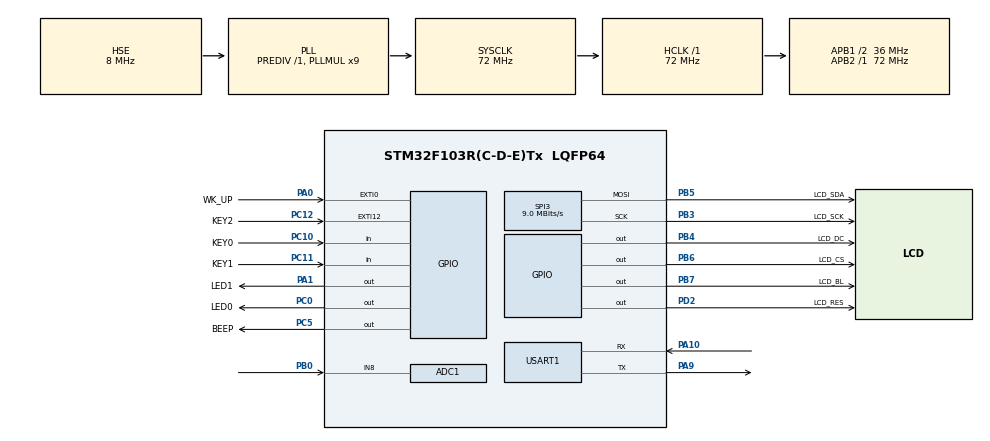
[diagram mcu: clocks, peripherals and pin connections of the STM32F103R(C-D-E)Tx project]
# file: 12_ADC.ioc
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ADC1.Channel-0\#ChannelRegularConversion=ADC_CHANNEL_8
ADC1.ContinuousConvMode=ENABLE
ADC1.NbrOfConversionFlag=1
ADC1.Rank-0\#ChannelRegularConversion=1
ADC1.SamplingTime-0\#ChannelRegularConversion=ADC_SAMPLETIME_1CYCLE_5
ADC1.master=1
Mcu.Family=STM32F1
Mcu.Name=STM32F103R(C-D-E)Tx
Mcu.Package=LQFP64
NVIC.EXTI0_IRQn=true\:2\:0\:true\:false\:true\:true\:true\:true
NVIC.EXTI15_10_IRQn=true\:2\:2\:true\:false\:true\:true\:true\:true
NVIC.PriorityGroup=NVIC_PRIORITYGROUP_2
NVIC.USART1_IRQn=true\:1\:0\:true\:false\:true\:true\:true\:true
PA0-WKUP.GPIO_Label=WK_UP
PA0-WKUP.GPIO_ModeDefaultEXTI=GPIO_MODE_IT_RISING
PA0-WKUP.GPIO_PuPd=GPIO_PULLDOWN
PA0-WKUP.Signal=GPXTI0
PA1.GPIO_Label=LED1
PA1.PinState=GPIO_PIN_SET
PA1.Signal=GPIO_Output
PA10.Mode=Asynchronous
PA10.Signal=USART1_RX
PA13.Mode=Serial_Wire
PA13.Signal=SYS_JTMS-SWDIO
PA14.Mode=Serial_Wire
PA14.Signal=SYS_JTCK-SWCLK
PA9.Mode=Asynchronous
PA9.Signal=USART1_TX
PB0.Signal=ADCx_IN8
PB3.GPIO_Label=LCD_SCK
PB3.Mode=TX_Only_Simplex_Unidirect_Master
PB3.Signal=SPI3_SCK
PB4.GPIO_Label=LCD_DC
PB4.GPIO_Speed=GPIO_SPEED_FREQ_HIGH
PB4.PinState=GPIO_PIN_SET
PB4.Signal=GPIO_Output
PB5.GPIO_Label=LCD_SDA
PB5.Mode=TX_Only_Simplex_Unidirect_Master
PB5.Signal=SPI3_MOSI
PB6.GPIO_Label=LCD_CS
PB6.GPIO_Speed=GPIO_SPEED_FREQ_HIGH
PB6.PinState=GPIO_PIN_SET
PB6.Signal=GPIO_Output
PB7.GPIO_Label=LCD_BL
PB7.Signal=GPIO_Output
PC0.GPIO_Label=LED0
PC0.PinState=GPIO_PIN_SET
PC0.Signal=GPIO_Output
PC10.GPIO_Label=KEY0
PC10.GPIO_PuPd=GPIO_PULLUP
PC10.Signal=GPIO_Input
PC11.GPIO_Label=KEY1
PC11.GPIO_PuPd=GPIO_PULLUP
PC11.Signal=GPIO_Input
PC12.GPIO_Label=KEY2
PC12.GPIO_ModeDefaultEXTI=GPIO_MODE_IT_FALLING
PC12.GPIO_PuPd=GPIO_PULLUP
PC12.Signal=GPXTI12
PC14-OSC32_IN.Mode=LSE-External-Oscillator
PC14-OSC32_IN.Signal=RCC_OSC32_IN
PC15-OSC32_OUT.Mode=LSE-External-Oscillator
PC15-OSC32_OUT.Signal=RCC_OSC32_OUT
PC5.GPIO_Label=BEEP
PC5.Signal=GPIO_Output
PD0-OSC_IN.Mode=HSE-External-Oscillator
PD0-OSC_IN.Signal=RCC_OSC_IN
PD1-OSC_OUT.Mode=HSE-External-Oscillator
PD1-OSC_OUT.Signal=RCC_OSC_OUT
PD2.GPIO_Label=LCD_RES
PD2.Signal=GPIO_Output
ProjectManager.HeapSize=0x200
ProjectManager.StackSize=0x400
ProjectManager.TargetToolchain=STM32CubeIDE
RCC.ADCPresc=RCC_ADCPCLK2_DIV6
RCC.AHBFreq_Value=72000000
RCC.APB1CLKDivider=RCC_HCLK_DIV2
RCC.APB1Freq_Value=36000000
RCC.APB1TimFreq_Value=72000000
RCC.APB2Freq_Value=72000000
RCC.APB2TimFreq_Value=72000000
RCC.HCLKFreq_Value=72000000
RCC.PLLMUL=RCC_PLL_MUL9
RCC.PLLSourceVirtual=RCC_PLLSOURCE_HSE
RCC.SYSCLKFreq_VALUE=72000000
RCC.SYSCLKSource=RCC_SYSCLKSOURCE_PLLCLK
RCC.USBFreq_Value=72000000
SH.ADCx_IN8.0=ADC1_IN8,IN8
SPI3.BaudRatePrescaler=SPI_BAUDRATEPRESCALER_4
SPI3.CalculateBaudRate=9.0 MBits/s
SPI3.Direction=SPI_DIRECTION_2LINES
SPI3.Mode=SPI_MODE_MASTER
SPI3.VirtualType=VM_MASTER
USART1.VirtualMode=VM_ASYNC
board=custom

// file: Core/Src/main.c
/* USER CODE BEGIN Header */
/**
  ******************************************************************************
  * @file           : main.c
  * @brief          : Main program body
  ******************************************************************************
  * @attention
  *
  * Copyright (c) 2025 STMicroelectronics.
  * All rights reserved.
  *
  * This software is licensed under terms that can be found in the LICENSE file
  * in the root directory of this software component.
  * If no LICENSE file comes with this software, it is provided AS-IS.
  *
  ******************************************************************************
  */
/* USER CODE END Header */
#include "main.h"
#include "adc.h"
#include "spi.h"
#include "usart.h"
#include "gpio.h"

/* USER CODE BEGIN Includes */
#include "common_inc.h"
#include "retarget.h"
/* USER CODE END Includes */

void SystemClock_Config(void);

int main(void)
{

  /* MCU Configuration--------------------------------------------------------*/

  /* Reset of all peripherals, Initializes the Flash interface and the Systick. */
  HAL_Init();

  /* Configure the system clock */
  SystemClock_Config();

  /* Initialize all configured peripherals */
  MX_GPIO_Init();
  MX_USART1_UART_Init();
  MX_SPI3_Init();
  MX_ADC1_Init();
  /* USER CODE BEGIN 2 */
  RetargetInit(&huart1);
  app_main();
  /* USER CODE END 2 */

  /* Infinite loop */
  while (1)
  {

  }
}

void SystemClock_Config(void)
{
  RCC_OscInitTypeDef RCC_OscInitStruct = {0};
  RCC_ClkInitTypeDef RCC_ClkInitStruct = {0};
  RCC_PeriphCLKInitTypeDef PeriphClkInit = {0};

  /** Initializes the RCC Oscillators according to the specified parameters
  * in the RCC_OscInitTypeDef structure.
  */
  RCC_OscInitStruct.OscillatorType = RCC_OSCILLATORTYPE_HSE;
  RCC_OscInitStruct.HSEState = RCC_HSE_ON;
  RCC_OscInitStruct.HSEPredivValue = RCC_HSE_PREDIV_DIV1;
  RCC_OscInitStruct.HSIState = RCC_HSI_ON;
  RCC_OscInitStruct.PLL.PLLState = RCC_PLL_ON;
  RCC_OscInitStruct.PLL.PLLSource = RCC_PLLSOURCE_HSE;
  RCC_OscInitStruct.PLL.PLLMUL = RCC_PLL_MUL9;
  if (HAL_RCC_OscConfig(&RCC_OscInitStruct) != HAL_OK)
  {
    Error_Handler();
  }

  /** Initializes the CPU, AHB and APB buses clocks
  */
  RCC_ClkInitStruct.ClockType = RCC_CLOCKTYPE_HCLK|RCC_CLOCKTYPE_SYSCLK
                              |RCC_CLOCKTYPE_PCLK1|RCC_CLOCKTYPE_PCLK2;
  RCC_ClkInitStruct.SYSCLKSource = RCC_SYSCLKSOURCE_PLLCLK;
  RCC_ClkInitStruct.AHBCLKDivider = RCC_SYSCLK_DIV1;
  RCC_ClkInitStruct.APB1CLKDivider = RCC_HCLK_DIV2;
  RCC_ClkInitStruct.APB2CLKDivider = RCC_HCLK_DIV1;

  if (HAL_RCC_ClockConfig(&RCC_ClkInitStruct, FLASH_LATENCY_2) != HAL_OK)
  {
    Error_Handler();
  }
  PeriphClkInit.PeriphClockSelection = RCC_PERIPHCLK_ADC;
  PeriphClkInit.AdcClockSelection = RCC_ADCPCLK2_DIV6;
  if (HAL_RCCEx_PeriphCLKConfig(&PeriphClkInit) != HAL_OK)
  {
    Error_Handler();
  }
}

void Error_Handler(void)
{
  __disable_irq();
  while (1)
  {
  }
}
